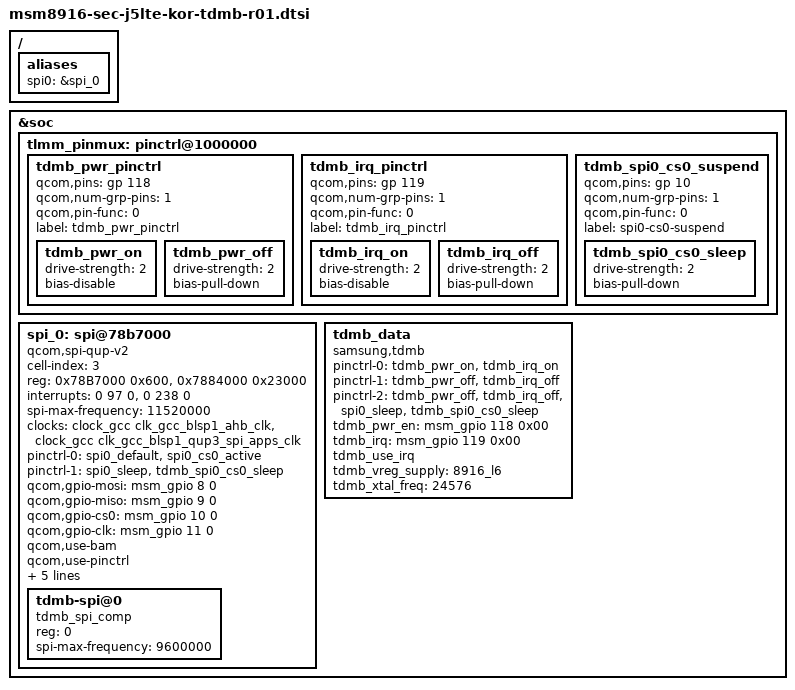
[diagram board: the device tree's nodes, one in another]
/* Copyright (c) 2012-2013, The Linux Foundation. All rights reserved.
 *
 * This program is free software; you can redistribute it and/or modify
 * it under the terms of the GNU General Public License version 2 and
 * only version 2 as published by the Free Software Foundation.
 *
 * This program is distributed in the hope that it will be useful,
 * but WITHOUT ANY WARRANTY; without even the implied warranty of
 * MERCHANTABILITY or FITNESS FOR A PARTICULAR PURPOSE.  See the
 * GNU General Public License for more details.
 */

/{
	aliases {
		spi0 = &spi_0;
	};
};

&soc {
	tlmm_pinmux: pinctrl@1000000 {
		tdmb_pwr_pinctrl {
			qcom,pins = <&gp 118>;
			qcom,num-grp-pins = <1>;
			qcom,pin-func = <0>;
			label = "tdmb_pwr_pinctrl";
			tdmb_pwr_on:tdmb_pwr_on {
				drive-strength = <2>;
				bias-disable;
			};
			tdmb_pwr_off: tdmb_pwr_off {
				drive-strength = <2>;
				bias-pull-down;
			};
		};
		tdmb_irq_pinctrl {
			qcom,pins = <&gp 119>;
			qcom,num-grp-pins = <1>;
			qcom,pin-func = <0>;
			label = "tdmb_irq_pinctrl";
			tdmb_irq_on: tdmb_irq_on {
				drive-strength = <2>;
				bias-disable;
			};
			tdmb_irq_off: tdmb_irq_off {
				drive-strength = <2>;
				bias-pull-down;
			};
		};
		tdmb_spi0_cs0_suspend {
			/* CS */
			qcom,pins = <&gp 10>;
			qcom,num-grp-pins = <1>;
			qcom,pin-func = <0>;
			label = "spi0-cs0-suspend";
			tdmb_spi0_cs0_sleep: tdmb_spi0_cs0_sleep {
				drive-strength = <2>;
				bias-pull-down;
			};
		};
	};

	spi_0: spi@78b7000 { /* BLSP1 QUP3 */
		compatible = "qcom,spi-qup-v2";
		cell-index = <3>;
		#address-cells = <1>;
		#size-cells = <0>;
		reg-names = "spi_physical", "spi_bam_physical";
		reg = <0x78B7000 0x600>, <0x7884000 0x23000>;
		interrupt-names = "spi_irq", "spi_bam_irq";
		interrupts = <0 97 0>, <0 238 0>;
		spi-max-frequency = <11520000>;
		clocks = <&clock_gcc clk_gcc_blsp1_ahb_clk>,
			 <&clock_gcc clk_gcc_blsp1_qup3_spi_apps_clk>;
		clock-names = "iface_clk", "core_clk";

		pinctrl-names = "default", "sleep";
		pinctrl-0 = <&spi0_default &spi0_cs0_active>;
		pinctrl-1 = <&spi0_sleep &tdmb_spi0_cs0_sleep>;

		qcom,gpio-mosi = <&msm_gpio 8 0>;
		qcom,gpio-miso = <&msm_gpio 9 0>;
		qcom,gpio-cs0 = <&msm_gpio 10 0>;
		qcom,gpio-clk = <&msm_gpio 11 0>;

		qcom,use-bam;
		qcom,use-pinctrl;
		qcom,bam-consumer-pipe-index = <8>;
		qcom,bam-producer-pipe-index = <9>;
		qcom,infinite-mode = <0>;
		qcom,ver-reg-exists;
		qcom,master-id = <86>;

		status = "ok";
		tdmb-spi@0 {
			compatible = "tdmb_spi_comp";
			reg = <0>;
			spi-max-frequency = <9600000>;
		};
	};

	tdmb_data {
		compatible = "samsung,tdmb";
		pinctrl-names = "tdmb_on", "tdmb_off", "tdmb_gpio_init";
		pinctrl-0 = <&tdmb_pwr_on &tdmb_irq_on>;
		pinctrl-1 = <&tdmb_pwr_off &tdmb_irq_off>;
		pinctrl-2 = <&tdmb_pwr_off &tdmb_irq_off &spi0_sleep &tdmb_spi0_cs0_sleep>;
		tdmb_pwr_en = <&msm_gpio 118 0x00>;
		tdmb_irq = <&msm_gpio 119 0x00>;
		tdmb_use_irq;
		tdmb_vreg_supply = "8916_l6";
		tdmb_xtal_freq = <24576>;
	};

};
